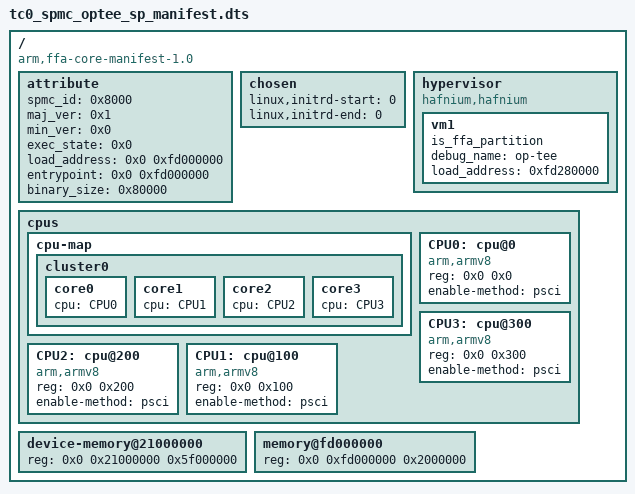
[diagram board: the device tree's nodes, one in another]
/*
 * Copyright (c) 2020, Arm Limited. All rights reserved.
 *
 * SPDX-License-Identifier: BSD-3-Clause
 */
/dts-v1/;

/ {
	compatible = "arm,ffa-core-manifest-1.0";
	#address-cells = <2>;
	#size-cells = <1>;

	attribute {
		spmc_id = <0x8000>;
		maj_ver = <0x1>;
		min_ver = <0x0>;
		exec_state = <0x0>;
		load_address = <0x0 0xfd000000>;
		entrypoint = <0x0 0xfd000000>;
		binary_size = <0x80000>;
	};

	chosen {
		linux,initrd-start = <0>;
		linux,initrd-end = <0>;
	};

	hypervisor {
		compatible = "hafnium,hafnium";
		vm1 {
			is_ffa_partition;
			debug_name = "op-tee";
			load_address = <0xfd280000>;
		};
	};

	cpus {
		#address-cells = <0x2>;
		#size-cells = <0x0>;

		cpu-map {
			cluster0 {
				core0 {
					cpu = <&CPU0>;
				};
				core1 {
					cpu = <&CPU1>;
				};
				core2 {
					cpu = <&CPU2>;
				};
				core3 {
					cpu = <&CPU3>;
				};
			};
		};

		CPU0:cpu@0 {
			device_type = "cpu";
			compatible = "arm,armv8";
			reg = <0x0 0x0>;
			enable-method = "psci";
		};

		/*
		 * SPMC (Hafnium) requires secondary cpu nodes are declared in
		 * descending order
		 */
		CPU3:cpu@300 {
			device_type = "cpu";
			compatible = "arm,armv8";
			reg = <0x0 0x300>;
			enable-method = "psci";
		};

		CPU2:cpu@200 {
			device_type = "cpu";
			compatible = "arm,armv8";
			reg = <0x0 0x200>;
			enable-method = "psci";
		};

		CPU1:cpu@100 {
			device_type = "cpu";
			compatible = "arm,armv8";
			reg = <0x0 0x100>;
			enable-method = "psci";
		};
	};

	device-memory@21000000 {
		device_type = "device-memory";
		reg = <0x0 0x21000000 0x5f000000>;
	};

	/* 32MB of TC0_TZC_DRAM1_BASE */
	memory@fd000000 {
		device_type = "memory";
		reg = <0x0 0xfd000000 0x2000000>;
	};
};
